# Montana register map
Vendor: ONSemiconductor; Series: Montana Series; File version: 1.0
CPU: CM33 r0p4, little endian, MPU, FPU, 3 interrupt priority bits
Registers are 32-bit, read-write, reset 0x0 unless marked. A register's access mark holds for its fields unless they carry their own. Offsets are from the block's base; [hi:lo] are bit positions; {n}, {i} and the like mark numbered series.

## ACS — Analog Control System
Base 0x40001600
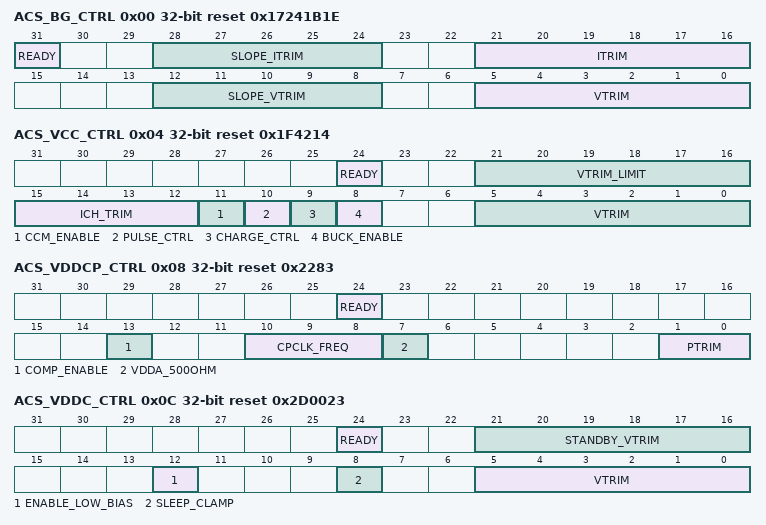
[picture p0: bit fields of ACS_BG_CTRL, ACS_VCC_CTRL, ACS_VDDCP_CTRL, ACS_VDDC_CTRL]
0x00 ACS_BG_CTRL reset 0x17241B1E — Bandgap Control register
  [31] READY ro — Bandgap ready
    0=BG_NOT_READY (Bandgap reference not ready); 1=BG_READY (Bandgap reference ready)
  [28:24] SLOPE_ITRIM — Current temperature coefficient trimming
    23=BG_SLOPE_ITRIM_VALUE (Current temperature dependency 0 ppm/C)
  [21:16] ITRIM — Reference current trimming
    0=BG_ITRIM_0P64UA (0.64 uA); 1=BG_ITRIM_0P65UA (0.65 uA); 35=BG_ITRIM_0P99UA (0.99 uA); 36=BG_ITRIM_1P00UA (1.00 uA); 37=BG_ITRIM_1P01UA (1.01 uA); 62=BG_ITRIM_1P26UA (1.26 uA); 63=BG_ITRIM_1P27UA (1.27 uA)
  [12:8] SLOPE_VTRIM — Voltage temperature coefficient trimming
    27=BG_SLOPE_VTRIM_VALUE (Voltage temperature dependency 0 ppm/C)
  [5:0] VTRIM — Reference voltage trimming (2.5 mV steps)
    0=BG_VTRIM_0P590V (0.610 V); 1=BG_VTRIM_0P595V (0.615 V); 27=BG_VTRIM_0P745V (0.745 V); 28=BG_VTRIM_0P750V (0.750 V); 29=BG_VTRIM_0P755V (0.755 V); 30=BG_VTRIM_0P760V (0.760 V); 31=BG_VTRIM_0P765V (0.765 V); 62=BG_VTRIM_0P900V (0.920 V); 63=BG_VTRIM_0P905V (0.925 V)
0x04 ACS_VCC_CTRL reset 0x1F4214 — DC-DC / LDO Supply Configuration / Control register
  [24] READY ro — Supply ready (only makes sense in test mode)
    0=VCC_NOT_READY (Supply voltage not ready); 1=VCC_READY (Supply voltage ready)
  [21:16] VTRIM_LIMIT — Max VTRIM value that can be used. If VTRIM value is greater it will be limited to this value
    0=VCC_TRIM_LIMIT_1P00V (Output voltage limit 1.00V); 5=VCC_TRIM_LIMIT_1P05V (Output voltage limit 1.05V); 10=VCC_TRIM_LIMIT_1P10V (Output voltage limit 1.10V); 15=VCC_TRIM_LIMIT_1P15V (Output voltage limit 1.15V); 20=VCC_TRIM_LIMIT_1P20V (Output voltage limit 1.20V); 25=VCC_TRIM_LIMIT_1P25V (Output voltage limit 1.25V); 31=VCC_TRIM_LIMIT_1P31V (Output voltage limit 1.31V (This should be the max value allowed)); 35=VCC_TRIM_LIMIT_1P35V (Output voltage limit 1.35V (This is the max value allowed only during RF operation at max output power)); 63=VCC_TRIM_LIMIT_1P63V (Output voltage limit 1.63V)
  [15:12] ICH_TRIM — Inductor charge current trimming
    0=VCC_ICHTRIM_16MA (Charge pump max current to 16 mA); 1=VCC_ICHTRIM_32MA (Charge pump max current to 32 mA); 3=VCC_ICHTRIM_64MA (Charge pump max current to 64 mA); 4=VCC_ICHTRIM_80MA (Charge pump max current to 80 mA); 15=VCC_ICHTRIM_256MA (Charge pump max current to 256 mA)
  [11] CCM_ENABLE — Enable CCM mode
    0=VCC_DCM_MODE (Discontinous current mode); 1=VCC_CCM_MODE (Continuous current mode enabled)
  [10] PULSE_CTRL — Pulse mode control
    0=VCC_SINGLE_PULSE (Single pulse per clock cycle); 1=VCC_MULTI_PULSE (Multi pulses enabled (until VCC > VCC_TRIM))
  [9] CHARGE_CTRL — Charge mode control
    0=VCC_CONSTANT_CHARGE (Constant charge transfer (valid for VBAT > VCC+0.2)); 1=VCC_CONSTANT_IMAX (Constant inductor maximum charge current)
  [8] BUCK_ENABLE — Enable buck converter mode
    0=VCC_LDO (Linear mode); 1=VCC_BUCK (Buck converter mode enabled)
  [5:0] VTRIM — Output voltage trimming configuration in 10 mV steps
    0=VCC_TRIM_1P00V (Output voltage 1.00V); 5=VCC_TRIM_1P05V (Output voltage 1.05V); 10=VCC_TRIM_1P10V (Output voltage 1.10V); 15=VCC_TRIM_1P15V (Output voltage 1.15V); 20=VCC_TRIM_1P20V (Output voltage 1.20V); 25=VCC_TRIM_1P25V (Output voltage 1.25V); 31=VCC_TRIM_1P31V (Output voltage 1.31V (This should be the max value allowed)); 35=VCC_TRIM_1P35V (Output voltage 1.35V (This is the absolute max value allowed, only for RF operation at max output power)); 63=VCC_TRIM_1P63V (Output voltage 1.63V)
0x08 ACS_VDDCP_CTRL reset 0x2283 — Charge Pump control register
  [24] READY ro — Supply ready
    0=VDDCP_NOT_READY (Charge pump voltage not ready); 1=VDDCP_READY (Charge pump voltage ready)
  [13] COMP_ENABLE — Force cp comparator enable
    0=VDDCP_COMP_AUTO (Comparator and resistive divider turned off when not required); 1=VDDCP_COMP_ENABLED (Comparator and resistive divider turned on (retro-compatible))
  [10:8] CPCLK_FREQ — Charge Pump clock frequency during power down modes
    0=VDDCP_CPCLK_32KHZ (CP clock = 32 kHz (WDG_SoC clock)); 1=VDDCP_CPCLK_16KHZ (CP clock = 16 kHz); 2=VDDCP_CPCLK_8KHZ (CP clock = 8 kHz); 3=VDDCP_CPCLK_4KHZ (CP clock = 4 kHz); 4=VDDCP_CPCLK_2KHZ (CP clock = 2 kHz); 5=VDDCP_CPCLK_1KHZ (CP clock = 1 kHz); 6=VDDCP_CPCLK_0P5KHZ (CP clock = 500 Hz); 7=VDDCP_CPCLK_0P25KHZ (CP clock = 250 Hz)
  [7] VDDA_500OHM — VDDA RC low impedance enable
    0=VDDCP_R5000 (5000 Ohm impedance); 1=VDDCP_R500 (500 Ohm impedance)
  [1:0] PTRIM — Output power trimming
    0=VDDCP_PTRIM_4MA (CP max current to 4 mA); 1=VDDCP_PTRIM_8MA (CP max current to 8 mA); 2=VDDCP_PTRIM_12MA (CP max current to 12 mA); 3=VDDCP_PTRIM_16MA (CP max current to 16 mA)
0x0C ACS_VDDC_CTRL reset 0x2D0023 — Digital Core Voltage Regulator control register
  [24] READY ro — Supply ready
    0=VDDC_NOT_READY (Supply voltage not ready); 1=VDDC_READY (Supply voltage ready)
  [21:16] STANDBY_VTRIM — VDDC standby voltage trimming (10 mV steps)
    0=VDDC_STANDBY_TRIM_0P75V (0.75 V); 1=VDDC_STANDBY_TRIM_0P76V (0.76 V); 45=VDDC_STANDBY_TRIM_1P20V (1.2 V); 57=VDDC_STANDBY_TRIM_1P32V (1.32 V); 63=VDDC_STANDBY_TRIM_1P38V (1.38 V)
  [12] ENABLE_LOW_BIAS — Low power mode control
    0=VDDC_NOMINAL_BIAS (Nominal regulator biasing); 1=VDDC_LOW_BIAS (Low regulator biasing)
  [8] SLEEP_CLAMP — Sleep mode clamp control
    0=VDDC_SLEEP_HIZ (Set the output HIZ (floating) in sleep mode); 1=VDDC_SLEEP_GND (Clamp output to ground in sleep mode)
  [5:0] VTRIM — Output voltage trimming configuration in 10 mV steps
    0=VDDC_TRIM_0P75V (0.75 V); 1=VDDC_TRIM_0P76V (0.76 V); 25=VDDC_TRIM_1P00V (1.0 V); 33=VDDC_TRIM_1P08V (1.08 V); 35=VDDC_TRIM_1P10V (1.1 V); 45=VDDC_TRIM_1P20V (1.2 V); 50=VDDC_TRIM_1P25V (1.25 V); 57=VDDC_TRIM_1P32V (1.32 V); 63=VDDC_TRIM_1P38V (1.38 V)
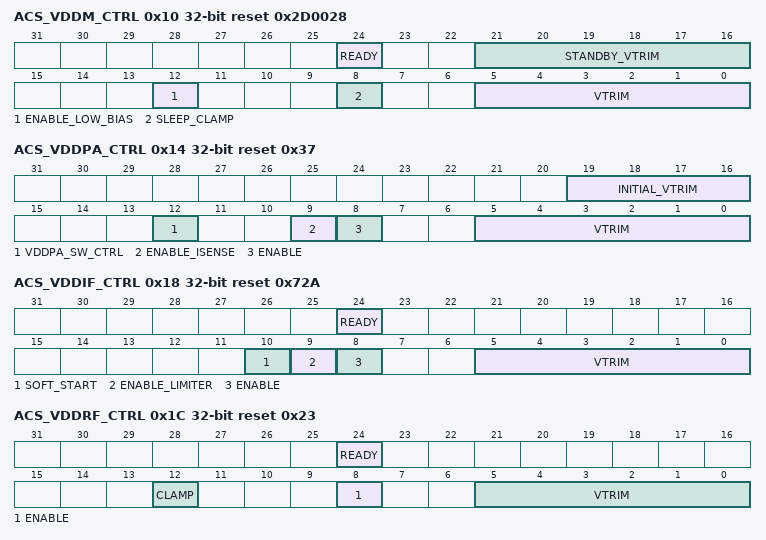
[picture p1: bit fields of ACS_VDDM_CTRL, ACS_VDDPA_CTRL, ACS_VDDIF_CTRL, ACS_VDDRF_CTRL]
0x10 ACS_VDDM_CTRL reset 0x2D0028 — Digital Core Voltage Regulator control register
  [24] READY ro — Supply ready
    0=VDDM_NOT_READY (Supply voltage not ready); 1=VDDM_READY (Supply voltage ready)
  [21:16] STANDBY_VTRIM — VDDM standby voltage trimming (10 mV steps)
    0=VDDM_STANDBY_TRIM_0P75V (0.75 V); 1=VDDM_STANDBY_TRIM_0P76V (0.76 V); 45=VDDM_STANDBY_TRIM_1P20V (1.2 V); 57=VDDM_STANDBY_TRIM_1P32V (1.32 V); 63=VDDM_STANDBY_TRIM_1P38V (1.38 V)
  [12] ENABLE_LOW_BIAS — Low power mode control
    0=VDDM_NOMINAL_BIAS (Nominal regulator biasing); 1=VDDM_LOW_BIAS (Low regulator biasing)
  [8] SLEEP_CLAMP — Sleep mode clamp control
    0=VDDM_SLEEP_HIZ (Set the output HIZ (floating) in sleep mode); 1=VDDM_SLEEP_GND (Clamp output to ground in sleep mode)
  [5:0] VTRIM — Output voltage trimming configuration in 10 mV steps
    0=VDDM_TRIM_0P75V (0.75 V); 1=VDDM_TRIM_0P76V (0.76 V); 25=VDDM_TRIM_1P00V (1.0 V); 33=VDDM_TRIM_1P08V (1.08 V); 35=VDDM_TRIM_1P10V (1.1 V); 40=VDDM_TRIM_1P15V (1.15 V); 45=VDDM_TRIM_1P20V (1.2 V); 50=VDDM_TRIM_1P25V (1.25 V); 57=VDDM_TRIM_1P32V (1.32 V); 63=VDDM_TRIM_1P38V (1.38 V)
0x14 ACS_VDDPA_CTRL reset 0x37 — RF Block Regulator Configuration / Control register
  [19:16] INITIAL_VTRIM — Initial output voltage trimming configuration in 10 mV steps
    0=VDDPA_INITIAL_TRIM_1P05V (1.05 V); 5=VDDPA_INITIAL_TRIM_1P10V (1.10 V); 15=VDDPA_INITIAL_TRIM_1P20V (1.20 V)
  [12] VDDPA_SW_CTRL — Power amplifier supply control
    0=VDDPA_SW_HIZ (Set the output HIZ (floating) in disable mode); 1=VDDPA_SW_VDDRF (Connect switched output to VDDRF regulator (ENABLE bit must be reset))
  [9] ENABLE_ISENSE — Enable current sensing circuit
    0=VDDPA_ISENSE_DISABLE (Disable the VDDPA regulator current sensing circuit); 1=VDDPA_ISENSE_ENABLE (Enable the VDDPA regulator current sensing circuit)
  [8] ENABLE — Enable control
    0=VDDPA_DISABLE (Disable the VDDPA regulator); 1=VDDPA_ENABLE (Enable the VDDPA regulator)
  [5:0] VTRIM — Output voltage trimming configuration in 10 mV steps
    0=VDDPA_TRIM_1P05V (1.05 V); 1=VDDPA_TRIM_1P06V (1.06 V); 54=VDDPA_TRIM_1P59V (1.59 V); 55=VDDPA_TRIM_1P60V (1.60 V); 56=VDDPA_TRIM_1P61V (1.61 V); 63=VDDPA_TRIM_1P68V (1.68 V)
0x18 ACS_VDDIF_CTRL reset 0x72A — VDDIF Block Regulator Configuration / Control register
  [24] READY ro — Supply ready
    0=VDDIF_NOT_READY (Supply voltage not ready); 1=VDDIF_READY (Supply voltage ready)
  [10] SOFT_START — Current limiter threshold setting
    0=VDDIF_LIMITER_70MA (Limiter current threshold at 70mA); 1=VDDIF_LIMITER_4MA (Limiter current threshold at 4mA)
  [9] ENABLE_LIMITER — Enable current limiter circuit
    0=VDDIF_LIMITER_DISABLE (Disable the VDDIF regulator current limiter circuit); 1=VDDIF_LIMITER_ENABLE (Enable the VDDIF regulator current limiter circuit)
  [8] ENABLE — Enable control
    0=VDDIF_DISABLE (Disable the VDDIF regulator); 1=VDDIF_ENABLE (Enable the VDDIF regulator)
  [5:0] VTRIM — Output voltage trimming configuration in 25 mV steps
    0=VDDIF_TRIM_0P750V (0.750V); 1=VDDIF_TRIM_0P775V (0.775V); 41=VDDIF_TRIM_1P775V (1.775V); 42=VDDIF_TRIM_1P800V (1.800V); 43=VDDIF_TRIM_1P825V (1.825V); 62=VDDIF_TRIM_2P300V (2.300V); 63=VDDIF_TRIM_2P325V (2.325V)
0x1C ACS_VDDRF_CTRL reset 0x23 — RF Regulator control register
  [24] READY ro — Supply ready
    0=VDDRF_NOT_READY (Supply voltage not ready); 1=VDDRF_READY (Supply voltage ready)
  [12] CLAMP — Disable mode clamp control
    0=VDDRF_DISABLE_HIZ (Set the output HIZ (floating) in disable mode); 1=VDDRF_DISABLE_GND (Clamp output to ground in disable mode)
  [8] ENABLE — Enable control
    0=VDDRF_DISABLE (Disable the VDDRF regulator); 1=VDDRF_ENABLE (Enable the VDDRF regulator)
  [5:0] VTRIM — Output voltage trimming configuration in 10 mV steps
    0=VDDRF_TRIM_0P75V (0.75 V); 1=VDDRF_TRIM_0P76V (0.76 V); 25=VDDRF_TRIM_1P00V (1.0 V); 33=VDDRF_TRIM_1P08V (1.08 V); 35=VDDRF_TRIM_1P10V (1.1 V); 45=VDDRF_TRIM_1P20V (1.2 V); 57=VDDRF_TRIM_1P32V (1.32 V); 63=VDDRF_TRIM_1P38V (1.38 V)
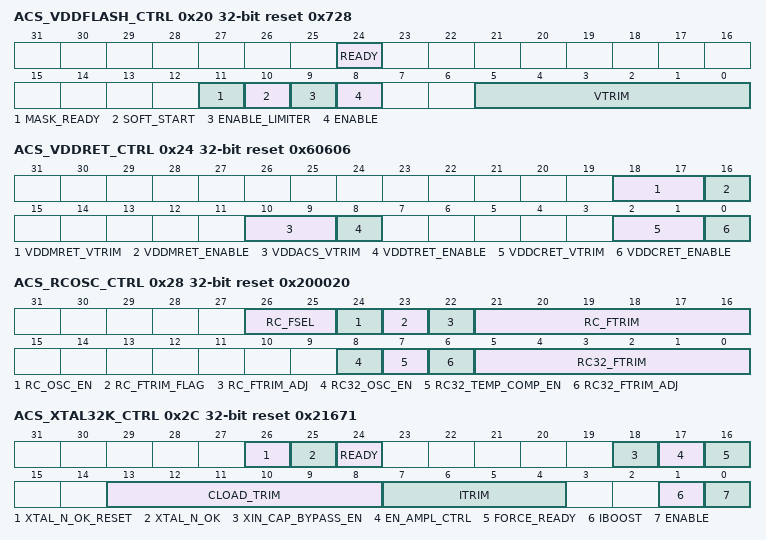
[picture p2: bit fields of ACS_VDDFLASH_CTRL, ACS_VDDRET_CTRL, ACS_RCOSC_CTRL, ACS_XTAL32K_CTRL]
0x20 ACS_VDDFLASH_CTRL reset 0x728 — VDDFLASH Block Regulator Configuration / Control register
  [24] READY ro — Supply ready
    0=VDDFLASH_NOT_READY (Supply voltage not ready); 1=VDDFLASH_READY (Supply voltage ready)
  [11] MASK_READY — Apply a mask to reset logic to ignore VDDFLASH ready signal
    0=VDDFLASH_USE_READY (Reset logic use VDDFLASH ready); 1=VDDFLASH_MASK_READY (Reset ignore VDDFLASH ready)
  [10] SOFT_START — Current limiter threshold setting
    0=VDDFLASH_LIMITER_70MA (Limiter current threshold at 70mA); 1=VDDFLASH_LIMITER_4MA (Limiter current threshold at 4mA)
  [9] ENABLE_LIMITER — Enable current limiter circuit
    0=VDDFLASH_LIMITER_DISABLE (Disable the VDDFLASH regulator current limiter circuit); 1=VDDFLASH_LIMITER_ENABLE (Enable the VDDFLASH regulator current limiter circuit)
  [8] ENABLE — Enable control
    0=VDDFLASH_DISABLE (Disable the VDDFLASH regulator); 1=VDDFLASH_ENABLE (Enable the VDDFLASH regulator)
  [5:0] VTRIM — Output voltage trimming configuration in 25 mV steps
    0=VDDFLASH_TRIM_0P750V (0.750V); 1=VDDFLASH_TRIM_0P775V (0.775V); 39=VDDFLASH_TRIM_1P725V (1.725V); 40=VDDFLASH_TRIM_1P750V (1.750V); 41=VDDFLASH_TRIM_1P775V (1.775V); 62=VDDFLASH_TRIM_2P300V (2.300V); 63=VDDFLASH_TRIM_2P325V (2.325V)
0x24 ACS_VDDRET_CTRL reset 0x60606 — Retention Regulator control register
  [18:17] VDDMRET_VTRIM — VDDMRET retention regulator voltage trimming
    3=VDDMRET_TRIM_VALUE (VDDMRET trimming value)
  [16] VDDMRET_ENABLE — Enable/Disable the VDDMRET retention regulator
    0=VDDMRET_DISABLE (The VDDMRET retention regulator is disabled); 1=VDDMRET_ENABLE (The VDDMRET retention regulator is enabled)
  [10:9] VDDACS_VTRIM — VDDACS regulator voltage trimming
    3=VDDACS_TRIM_VALUE (VDDACS trimming value)
  [8] VDDTRET_ENABLE — Enables the VDDT retention power (activate switch from VDDACS)
    0=VDDTRET_DISABLE (Disable BB timer retention supply (VDDT)); 1=VDDTRET_ENABLE (Enable BB timer retention supply (VDDT))
  [2:1] VDDCRET_VTRIM — VDDCRET Retention regulator voltage trimming
    3=VDDCRET_TRIM_VALUE (VDDCRET trimming value)
  [0] VDDCRET_ENABLE — Enables the VDDCRET Retention regulator
    0=VDDCRET_DISABLE (The VDDCRET retention regulator is disabled); 1=VDDCRET_ENABLE (The VDDCRET retention regulator is enabled)
0x28 ACS_RCOSC_CTRL reset 0x200020 — RC Oscillator control register
  [26:25] RC_FSEL — Select RC oscillator frequency
    0=RC_OSC_3MHZ (The RC Oscillator is at 3 MHz); 1=RC_OSC_12MHZ (The RC Oscillator is at 12 MHz); 2=RC_OSC_24MHZ (The RC Oscillator is at 24 MHz); 3=RC_OSC_48MHZ (The RC Oscillator is at 48 MHz)
  [24] RC_OSC_EN — Enable/Disable the RC Oscillator
    0=RC_OSC_AUTO (The RC Oscillator is in auto mode); 1=RC_OSC_ENABLE (The RC Oscillator is enabled)
  [23] RC_FTRIM_FLAG — RC Oscillator Trimming flag
    0=RC_OSC_UNCALIBRATED (The oscillators are not calibrated); 1=RC_OSC_CALIBRATED (The oscillators are calibrated)
  [22] RC_FTRIM_ADJ — Adjust RC oscillator frequency range
    0=RC_OSC_RANGE_NOM (The RC Oscillator frequency range is nominal); 1=RC_OSC_RANGE_M15 (The RC Osc higher trim freq is decreased by 15 percent)
  [21:16] RC_FTRIM — RC oscillator frequency trimming
    0=RC_OSC_M48 (-48 percent trimming); 1=RC_OSC_M46P5 (-46.5 percent trimming); 32=RC_OSC_NOM (Nominal frequency); 63=RC_OSC_P46P5 (+46.5 percent trimming)
  [8] RC32_OSC_EN — Enable/Disable the 32 kHz RC Oscillator
    0=RC32_OSC_DISABLE (The 32kHz RC Oscillator is disabled); 1=RC32_OSC_ENABLE (The 32kHz RC Oscillator is enabled)
  [7] RC32_TEMP_COMP_EN — Enable/Disable the 32 kHz RC Oscillator
    0=RC32_TEMP_COMP_DISABLE (The 32kHz RC Oscillator temperature compensation is disabled); 1=RC32_TEMP_COMP_ENABLE (The 32kHz RC Oscillator temperature compensation is enabled)
  [6] RC32_FTRIM_ADJ — Adjust 32 kHz RC oscillator frequency range
    0=RC32_OSC_RANGE_NOM (The 32 kHz RC Oscillator frequency range is nominal); 1=RC32_OSC_RANGE_M25 (The 32 kHz RC Oscillator frequency range is lowered by 25 percent)
  [5:0] RC32_FTRIM — 32 kHz RC oscillator frequency trimming
    0=RC32_OSC_M48 (-48 percent trimming); 1=RC32_OSC_M46P5 (-46.5 percent trimming); 32=RC32_OSC_NOM (Nominal frequency); 63=RC32_OSC_P46P5 (+46.5 percent trimming)
0x2C ACS_XTAL32K_CTRL reset 0x21671 (reset mask 0x3073FF3) — Xtal 32 kHz configuration register
  [26] XTAL_N_OK_RESET wo — Reset Xtal not ok sticky flag
    1=XTAL32K_NOT_OK_RESET (Xtal 32K not reset)
  [25] XTAL_N_OK ro — Xtal not ready sticky flag
    0=XTAL_OK (Xtal 32K NOT OK sticky flag was not set); 1=XTAL_N_OK (Xtal 32K NOT OK sticky flag was set)
  [24] READY ro — Xtal ready status
    0=XTAL32K_NOT_OK (Xtal 32K not available); 1=XTAL32K_OK (Xtal 32K is OK)
  [18] XIN_CAP_BYPASS_EN — Switch to bypass the added XIN serial cap to reduce the leakage
    0=XTAL32K_XIN_CAP_BYPASS_DISABLE (Disable the Xtal bypass switch of the XIN serial cap); 1=XTAL32K_XIN_CAP_BYPASS_ENABLE (Enable the Xtal bypass switch of the XIN serial cap)
  [17] EN_AMPL_CTRL — Xtal enable amplitude control (regulation)
    0=XTAL32K_AMPL_CTRL_DISABLE (Xtal 32K amplitude control disabled); 1=XTAL32K_AMPL_CTRL_ENABLE (Xtal 32K amplitude control enabled)
  [16] FORCE_READY — Xtal bypass the ready detector
    0=XTAL32K_NOT_FORCE_READY (Xtal 32K ready not forced); 1=XTAL32K_FORCE_READY (Xtal 32K ready forced)
  [13:8] CLOAD_TRIM — Xtal load capacitance configuration
    0=XTAL32K_CTRIM_0P0PF (0 pF internal capacitor); 1=XTAL32K_CTRIM_0P4PF (0.4 pF internal capacitor); 22=XTAL32K_CTRIM_8P8PF (8.8 pF internal capacitor); 63=XTAL32K_CTRIM_25P2PF (25.2 pF internal capacitor)
  [7:4] ITRIM — Xtal current trimming
    0=XTAL32K_ITRIM_20NA (20 nA startup current); 3=XTAL32K_ITRIM_80NA (80 nA startup current); 7=XTAL32K_ITRIM_160NA (160 nA startup current); 15=XTAL32K_ITRIM_320NA (320 nA startup current)
  [1] IBOOST — Xtal current boosting (4x)
    0=XTAL32K_IBOOST_DISABLE (Disable the Xtal 32 kHz current boosting mode); 1=XTAL32K_IBOOST_ENABLE (Disable the Xtal 32 kHz enable boosting mode (4x itrim currents))
  [0] ENABLE — Enable the Xtal 32 kHz oscillator
    0=XTAL32K_DISABLE (Disable the Xtal 32 kHz oscillator); 1=XTAL32K_ENABLE (Enable the Xtal 32 kHz oscillator)
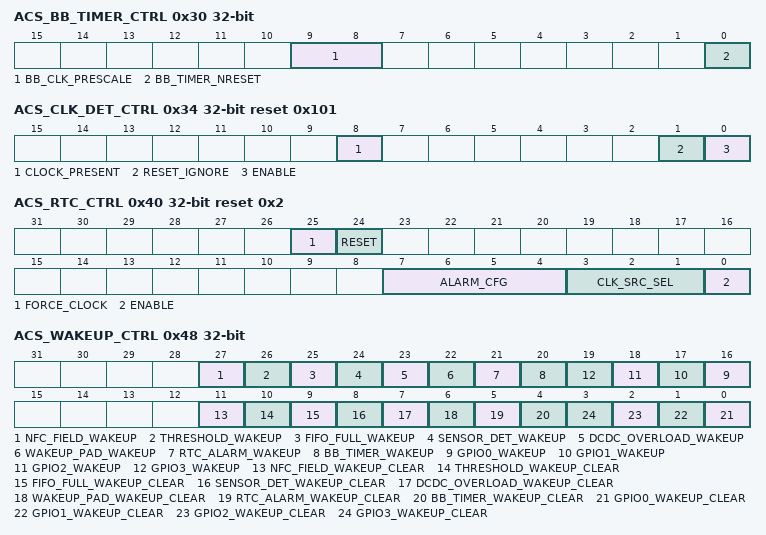
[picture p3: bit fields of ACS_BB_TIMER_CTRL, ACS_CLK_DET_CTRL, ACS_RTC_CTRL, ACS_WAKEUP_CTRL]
0x30 ACS_BB_TIMER_CTRL — Baseband timer and standby clock control register
  [9:8] BB_CLK_PRESCALE — Prescale value for the baseband timer clock
    0=Use 32 kHz clock from RTC; 1=Use 16 kHz clock from RTC (counter bit0); 2=Use 8 kHz clock from RTC (counter bit1); 3=Use 4 kHz clock from RTC (counter bit2)
  [0] BB_TIMER_NRESET — nReset signal for the baseband timer
    0=BB_TIMER_RESET (Baseband timer is in reset state); 1=BB_TIMER_NRESET (Baseband timer reset is released)
0x34 ACS_CLK_DET_CTRL reset 0x101 — Clock Detector configuration register
  [8] CLOCK_PRESENT ro — Clock present flag
    0=ACS_CLK_DET_NO_CLOCK (No clock detected); 1=ACS_CLK_DET_CLOCK_PRESENT (Clock detected)
  [1] RESET_IGNORE — Clock detector reset condition ignore
    1=ACS_CLK_DET_RESET_DISABLE (Clock detector reset condition ignore); 0=ACS_CLK_DET_RESET_ENABLE (Clock detector reset condition accept)
  [0] ENABLE — Clock detector enable
    1=ACS_CLK_DET_ENABLE (Clock detector enable); 0=ACS_CLK_DET_DISABLE (Clock detector disable)
0x38 ACS_RTC_CFG reset 0x7FFF — RTC Timer Counter Preload
  [31:0] START_VALUE — Start value for the RTC timer counter (counts from start_value down to 0)
    0=RTC_CNT_START_0 (Divide by 1); 1=RTC_CNT_START_1 (Divide by 2); 0x7FFF=RTC_CNT_START_32767 (Divide by 32768); 0xFFFFFFFF=RTC_CNT_START_4294967295 (Divide by 2**32)
0x3C ACS_RTC_COUNT ro — RTC Timer Counter Current Value
  [31:0] VALUE — RTC timer current value
0x40 ACS_RTC_CTRL reset 0x2 (reset mask 0xFF) — RTC control Register
  [25] FORCE_CLOCK wo — Force a clock on RTC timer (Test Purpose)
    1=RTC_FORCE_CLOCK (Clock the RTC timer (has an effect only if the source clock is low))
  [24] RESET wo — Reset the RTC timer
    1=RTC_RESET (The RTC timer is reset)
  [7:4] ALARM_CFG — Configure RTC timer alarm
    0=RTC_ALARM_DISABLE (RTC alarm is disabled); 1=RTC_ALARM_7P8125MS (RTC alarm on counter bit 7th rising edge (7.8125 ms = 2^(n+1)*1/32.768kHz)); 2=RTC_ALARM_15P625MS (RTC alarm on counter bit 8th rising edge (15.625 ms = 2^(n+1)*1/32.768kHz)); 3=RTC_ALARM_31P25MS (RTC alarm on counter bit 9th rising edge (31.25 ms = 2^(n+1)*1/32.768kHz)); 4=RTC_ALARM_62P5MS (RTC alarm on counter bit 10th rising edge (62.5 ms = 2^(n+1)*1/32.768kHz)); 5=RTC_ALARM_125MS (RTC alarm on counter bit 11th rising edge (125 ms = 2^(n+1)*1/32.768kHz)); 6=RTC_ALARM_250MS (RTC alarm on counter bit 12th rising edge (250 ms = 2^(n+1)*1/32.768kHz)); 7=RTC_ALARM_500MS (RTC alarm on counter bit 13th rising edge (500 ms = 2^(n+1)*1/32.768kHz)); 8=RTC_ALARM_1S (RTC alarm on counter bit 14th rising edge (1 s = 2^(n+1)*1/32.768kHz)); 9=RTC_ALARM_2S (RTC alarm on counter bit 15th rising edge (2 s = 2^(n+1)*1/32.768kHz)); 10=RTC_ALARM_4S (RTC alarm on counter bit 16th rising edge (4 s = 2^(n+1)*1/32.768kHz)); 11=RTC_ALARM_8S (RTC alarm on counter bit 17th rising edge (8 s = 2^(n+1)*1/32.768kHz)); 12=RTC_ALARM_16S (RTC alarm on counter bit 18th rising edge (16 s = 2^(n+1)*1/32.768kHz)); 13=RTC_ALARM_32S (RTC alarm on counter bit 19th rising edge (32 s = 2^(n+1)*1/32.768kHz)); 14=RTC_ALARM_64S (RTC alarm on counter bit 20th rising edge (64 s = 2^(n+1)*1/32.768kHz)); 15=RTC_ALARM_ZERO (RTC alarm on (down with RTC clock input is 32.768 kHz) counter reaching zero (up to 36.4 hours))
  [3:1] CLK_SRC_SEL — Select the RTC, standby, bb timer, and sensor block clock source
    0=RTC_CLK_SRC_RC_OSC (Select the internal RC Oscillator clock); 1=RTC_CLK_SRC_XTAL32K (Select the internal XTAL 32 kHz clock); 2=RTC_CLK_SRC_GPIO0 (Select GPIO0 as a clock source); 3=RTC_CLK_SRC_GPIO1 (Select GPIO1 as a clock source); 4=RTC_CLK_SRC_GPIO2 (Select GPIO2 as a clock source (not functional, test purpose only)); 5=RTC_CLK_SRC_GPIO3 (Select GPIO3 as a clock source (not functional, test purpose only))
  [0] ENABLE — Enable counter and RTC interrupt every 1s
    0=RTC_DISABLE (The RTC is disabled); 1=RTC_ENABLE (The RTC is enabled)
0x44 ACS_PWR_MODES_CTRL reset not defined — Power Modes control Register
  [31:0] POWER_MODE wo — 32-bit key to enter STANDBY, SLEEP, or DEEP_SLEEP mode. This register must be written using a 32-bit access.
    0=PWR_RUN_MODE (Keep the system in normal RUN mode); 0x9B1D79A0=PWR_STANDBY_MODE (Enter STANDBY mode); 0xE0045650=PWR_SLEEP_MODE (Enter SLEEP mode); 0x53C02890=PWR_DEEP_SLEEP_MODE (Enter DEEP_SLEEP mode)
0x48 ACS_WAKEUP_CTRL (reset mask 0xFFF0000) — Wake-Up control / Status Register
  [27] NFC_FIELD_WAKEUP ro
    0=WAKEUP_NFC_FIELD_EVENT_NOT_SET (NFC field has not triggered a wakeup event); 1=WAKEUP_NFC_FIELD_EVENT_SET (NFC field has triggered a wakeup event at least once)
  [26] THRESHOLD_WAKEUP ro
    0=WAKEUP_THRESHOLD_EVENT_NOT_SET (The ADC threshold has not triggered a wakeup event); 1=WAKEUP_THRESHOLD_EVENT_SET (The ADC threshold has triggered a wakeup event at least once)
  [25] FIFO_FULL_WAKEUP ro
    0=WAKEUP_FIFO_FULL_EVENT_NOT_SET (The ADC FIFO has not triggered a wakeup event); 1=WAKEUP_FIFO_FULL_EVENT_SET (The ADC FIFO has triggered a wakeup event at least once)
  [24] SENSOR_DET_WAKEUP ro
    0=WAKEUP_SENSOR_DET_EVENT_NOT_SET (Sensor detector has not triggered a wakeup event); 1=WAKEUP_SENSOR_DET_EVENT_SET (Sensor detector has triggered a wakeup event at least once)
  [23] DCDC_OVERLOAD_WAKEUP ro
    0=WAKEUP_DCDC_OVERLOAD_EVENT_NOT_SET (DCDC overload has not triggered a wakeup event); 1=WAKEUP_DCDC_OVERLOAD_EVENT_SET (DCDC overload has triggered a wakeup event at least once)
  [22] WAKEUP_PAD_WAKEUP ro
    0=WAKEUP_PAD_EVENT_NOT_SET (Wakeup pad has not triggered a wakeup event); 1=WAKEUP_PAD_EVENT_SET (Wakeup pad has triggered a wakeup event at least once)
  [21] RTC_ALARM_WAKEUP ro
    0=WAKEUP_RTC_ALARM_EVENT_NOT_SET (RTC alarm has not triggered a wakeup event); 1=WAKEUP_RTC_ALARM_EVENT_SET (RTC alarm has triggered a wakeup event at least once)
  [20] BB_TIMER_WAKEUP ro
    0=WAKEUP_BB_TIMER_EVENT_NOT_SET (BB timer has not triggered a wakeup event); 1=WAKEUP_BB_TIMER_EVENT_SET (BB timer has triggered a wakeup event at least once)
  [n+16] GPIO{n}_WAKEUP ro (n=0..3)
    0=WAKEUP_GPIO{n}_EVENT_NOT_SET (GPIO{n} has not triggered a wakeup event); 1=WAKEUP_GPIO{n}_EVENT_SET (GPIO{n} has triggered a wakeup event at least once)
  [11] NFC_FIELD_WAKEUP_CLEAR wo
    1=WAKEUP_NFC_FIELD_EVENT_CLEAR (Reset the sticky WAKEUP_NFC_FIELD_EVENT flag)
  [10] THRESHOLD_WAKEUP_CLEAR wo
    1=THRESHOLD_FULL_EVENT_CLEAR (Reset the sticky WAKEUP_THRESHOLD_EVENT flag)
  [9] FIFO_FULL_WAKEUP_CLEAR wo
    1=WAKEUP_FIFO_FULL_EVENT_CLEAR (Reset the sticky WAKEUP_FIFO_FULL_EVENT flag)
  [8] SENSOR_DET_WAKEUP_CLEAR wo
    1=WAKEUP_SENSOR_DET_EVENT_CLEAR (Reset the sticky WAKEUP_SENSOR_DET_EVENT flag)
  [7] DCDC_OVERLOAD_WAKEUP_CLEAR wo
    1=WAKEUP_DCDC_OVERLOAD_EVENT_CLEAR (Reset the sticky WAKEUP_DCDC_OVERLOAD flag)
  [6] WAKEUP_PAD_WAKEUP_CLEAR wo
    1=WAKEUP_PAD_EVENT_CLEAR (Reset the sticky WAKEUP_PAD_EVENT flag)
  [5] RTC_ALARM_WAKEUP_CLEAR wo
    1=WAKEUP_RTC_ALARM_EVENT_CLEAR (Reset the sticky WAKEUP_RTC_ALARM_EVENT flag)
  [4] BB_TIMER_WAKEUP_CLEAR wo
    1=WAKEUP_BB_TIMER_CLEAR (Reset the sticky WAKEUP_BB_TIMER_EVENT flag)
  [n] GPIO{n}_WAKEUP_CLEAR wo (n=0..3)
    1=WAKEUP_GPIO{n}_EVENT_CLEAR (Reset the sticky WAKEUP_GPIO{n}_EVENT flag)
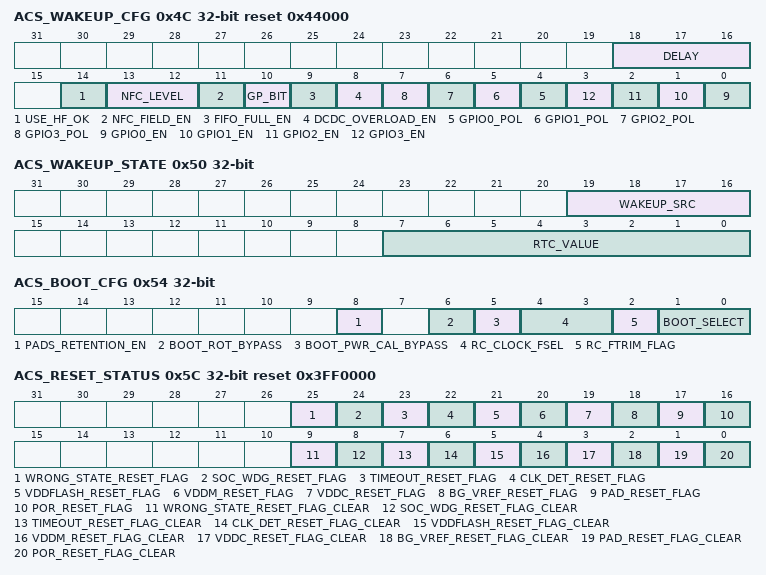
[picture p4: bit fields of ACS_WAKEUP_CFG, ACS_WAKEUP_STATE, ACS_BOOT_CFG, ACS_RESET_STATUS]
0x4C ACS_WAKEUP_CFG reset 0x44000 — Wakeup configuration
  [18:16] DELAY — Delay from VDDC ready & VDDM ready to digital clock enable (power of 2)
    0=WAKEUP_DELAY_1 (Wait for 1 32kHz clock cycle); 1=WAKEUP_DELAY_2 (Wait for 2 32kHz clock cycles); 2=WAKEUP_DELAY_4 (Wait for 4 32kHz clock cycles); 3=WAKEUP_DELAY_8 (Wait for 8 32kHz clock cycles); 4=WAKEUP_DELAY_16 (Wait for 16 32kHz clock cycles); 5=WAKEUP_DELAY_32 (Wait for 32 32kHz clock cycles); 6=WAKEUP_DELAY_64 (Wait for 64 32kHz clock cycles); 7=WAKEUP_DELAY_128 (Wait for 128 32kHz clock cycles)
  [14] USE_HF_OK — Ignore the status of HF clock frequency to wake-up the SoC
    0=WAKEUP_NOT_USE_HF_OK (Wake-up don't use HF OK); 1=WAKEUP_USE_HF_OK
  [13:12] NFC_LEVEL — Level of the NFC field to wake up the SoC
    0=NFC_FIELD_0 (Level 0 of the field triggers wake-up); 1=NFC_FIELD_1 (Level 1 of the field triggers wake-up); 2=NFC_FIELD_2 (Level 2 of the field triggers wake-up)
  [11] NFC_FIELD_EN — Enable the wake-up on NFC field
    0=WAKEUP_NFC_FIELD_DISABLE (Disable NFC field wake-up); 1=WAKEUP_NFC_FIELD_ENABLE (Enable NFC field interrupt wake-up)
  [10] GP_BIT — This bit is a RW flop that is not used by the HW
  [9] FIFO_FULL_EN — Enable the wake-up on full FIFO
    0=WAKEUP_FIFO_DISABLE (Disable the wake-up functionality on the ADC FIFO); 1=WAKEUP_FIFO_ENABLE (Enable the wake-up functionality on the ADC FIFO)
  [8] DCDC_OVERLOAD_EN — Enable / Disable the Wake-up functionality on the DCDC overload flag
    0=WAKEUP_DCDC_OVERLOAD_DISABLE (Disable the Wake-up functionality on the DCDC overload flag); 1=WAKEUP_DCDC_OVERLOAD_ENABLE (Enable the Wake-up functionality on the DCDC overload flag)
  [n+4] GPIO{n}_POL (n=0..3) — Wake-up polarity on the GPIO{n} pad
    0=WAKEUP_GPIO{n}_RISING (Wake-up on the GPIO{n} rising edge); 1=WAKEUP_GPIO{n}_FALLING (Wake-up on the GPIO{n} falling edge)
  [n] GPIO{n}_EN (n=0..3) — Enable the wake-up functionality on the GPIO{n} pad
    0=WAKEUP_GPIO{n}_DISABLE (Disable the wake-up functionality on the GPIO{n} pad); 1=WAKEUP_GPIO{n}_ENABLE (Enable the wake-up functionality on the GPIO{n} pad)
0x50 ACS_WAKEUP_STATE ro — RTC Timer wakeup value and wakeup source
  [19:16] WAKEUP_SRC — Status register indicates the last wake-up source
    11=WAKEUP_DUE_TO_NFC_FIELD (The last wake-up was due to the NFC field); 10=WAKEUP_DUE_TO_THRESHOLD (The last wake-up was due to the ADC threshold); 9=WAKEUP_DUE_TO_FIFO (The last wake-up was due to the ADC FIFO); 8=WAKEUP_DUE_TO_SENSOR_DET (The last wake-up was due to the sensor detector); 7=WAKEUP_DUE_TO_DCDC_OVERLOAD (The last wake-up was due to the dcdc overload); 6=WAKEUP_DUE_TO_WAKEUP_PAD (The last wake-up was due to the WAKEUP pad); 5=WAKEUP_DUE_TO_RTC_ALARM (The last wake-up was due to the RTC Timer alarm); 4=WAKEUP_DUE_TO_BB_TIMER (The last wake-up was due to the baseband timer alarm); {v}=WAKEUP_DUE_TO_GPIO{v} (The last wake-up was due to the GPIO{v} pad) (v=0..3)
  [7:0] RTC_VALUE — RTC counter value captured at wakeup event (only 8 LSBs, corresponds to 7.8 ms)
0x54 ACS_BOOT_CFG — Boot configuration
  [8] PADS_RETENTION_EN — Enable / Disable the retention mode of the pads
    0=PADS_RETENTION_DISABLE (Disable the pad retention mode); 1=PADS_RETENTION_ENABLE (Enable the pad retention mode)
  [6] BOOT_ROT_BYPASS — Boot bypass execution of root of trust
    0=BOOT_ROT_BYPASS_DISABLE (ROM will execute ROT); 1=BOOT_ROT_BYPASS_ENABLE (ROM will not execute ROT)
  [5] BOOT_PWR_CAL_BYPASS — Boot bypass execution of system calibration
    0=BOOT_PWR_CAL_BYPASS_DISABLE (ROM will execute calibration of system); 1=BOOT_PWR_CAL_BYPASS_ENABLE (ROM will not execute calibration of system)
  [4:3] RC_CLOCK_FSEL ro — RC oscillator clock multiplier read only flag (mirror of CLOCK_MULT of ACS_RCOSC_CTRL register)
    0=RC_OSC_STATUS_3MHZ (The RC Oscillator is at 3 MHz); 1=RC_OSC_STATUS_12MHZ (The RC Oscillator is at 12 MHz); 2=RC_OSC_STATUS_24MHZ (The RC Oscillator is at 24 MHz); 3=RC_OSC_STATUS_48MHZ (The RC Oscillator is at 48 MHz)
  [2] RC_FTRIM_FLAG ro — RC oscillator trimming read only flag (mirror of FTRIM_FLAG of ACS_RCOSC_CTRL register
    0=RC_OSC_STATUS_UNCALIBRATED (The oscillators are not calibrated); 1=RC_OSC_STATUS_CALIBRATED (The oscillators are calibrated)
  [1:0] BOOT_SELECT — Boot selection to indicate boot source
    0=BOOT_FLASH_XTAL_DISABLE (The CM33 executes code from the flash and the XTAL will not be started at boot); 1=BOOT_CUSTOM (The CM33 executes code from the address specified in the wakeup information in retention RAM and the XTAL will not be started at boot); 2=BOOT_FLASH_XTAL_DEFAULT_TRIM (The CM33 executes code from the flash and the XTAL will be started at boot with the default trim); 3=BOOT_FLASH_XTAL_CUSTOM_TRIM (The CM33 executes code from the flash and the XTAL will be started at boot with trim from ACS_WAKEUP_GP_DATA)
0x58 ACS_BOOT_GP_DATA — Boot control Register registers
  [31:0] GP_DATA — 32-bit General-Purpose RW Data
0x5C ACS_RESET_STATUS reset 0x3FF0000 (reset mask 0x3FF0000) — ACS reset source status registers
  [25] WRONG_STATE_RESET_FLAG ro — Sticky flag that detects that a wrong state reset occurred
    0=WRONG_STATE_RESET_FLAG_NOT_SET (The wrong state reset has not triggered at least once); 1=WRONG_STATE_RESET_FLAG_SET (The wrong state reset was triggered at least once since this status bit was last cleared)
  [24] SOC_WDG_RESET_FLAG ro — Sticky flag that detects that a SoC watchdog reset occurred
    0=SOC_WDG_RESET_FLAG_NOT_SET (The SoC watchdog reset has not triggered at least once); 1=SOC_WDG_RESET_FLAG_SET (The SoC watchdog reset was triggered at least once since this status bit was last cleared)
  [23] TIMEOUT_RESET_FLAG ro — Sticky flag that detects that a timeout in the power up sequence
    0=TIMEOUT_RESET_FLAG_NOT_SET (The timeout reset has not triggered at least once); 1=TIMEOUT_RESET_FLAG_SET (The timeout reset was triggered at least once since this status bit was last cleared)
  [22] CLK_DET_RESET_FLAG ro — Sticky flag that detects that a clock detector reset occurred
    0=CLK_DET_RESET_FLAG_NOT_SET (The clock detector reset has not triggered at least once); 1=CLK_DET_RESET_FLAG_SET (The clock detector reset was triggered at least once since this status bit was last cleared)
  [21] VDDFLASH_RESET_FLAG ro — Sticky flag that detects that a VDDFLASH reset occurred (triggered by VDDFLASH_ready = 0)
    0=VDDFLASH_RESET_FLAG_NOT_SET (The VDDFLASH reset has not triggered at least once); 1=VDDFLASH_RESET_FLAG_SET (The VDDFLASH reset was triggered at least once since this status bit was last cleared)
  [20] VDDM_RESET_FLAG ro — Sticky flag that detects that a VDDM reset occurred (triggered by VDDM_ready = 0)
    0=VDDM_RESET_FLAG_NOT_SET (The VDDM reset has not triggered at least once); 1=VDDM_RESET_FLAG_SET (The VDDM reset was triggered at least once since this status bit was last cleared)
  [19] VDDC_RESET_FLAG ro — Sticky flag that detects that a VDDC reset occurred (triggered by VDDC_ready = 0)
    0=VDDC_RESET_FLAG_NOT_SET (The VDDC reset has not triggered at least once); 1=VDDC_RESET_FLAG_SET (The VDDC reset was triggered at least once since this status bit was last cleared)
  [18] BG_VREF_RESET_FLAG ro — Sticky flag that detects that a Bandagap reference voltage reset occurred
    0=BG_VREF_RESET_FLAG_NOT_SET (The Bandagap reference voltage reset has not triggered at least once); 1=BG_VREF_RESET_FLAG_SET (The Bandagap reference voltage was triggered at least once since this status bit was last cleared)
  [17] PAD_RESET_FLAG ro — Sticky flag that detects that a reset occurred due to pad NRESET
    0=PAD_RESET_FLAG_NOT_SET (The NRESET pad reset has not triggered at least once); 1=PAD_RESET_FLAG_SET (The NRESET pad reset was triggered at least once since this status bit was last cleared)
  [16] POR_RESET_FLAG ro — Sticky flag that detects that a POR reset occurred
    0=POR_RESET_FLAG_NOT_SET (The POR reset has not triggered at least once); 1=POR_RESET_FLAG_SET (The POR reset was triggered at least once since this status bit was last cleared)
  [9] WRONG_STATE_RESET_FLAG_CLEAR wo — Reset the sticky WRONG_STATE_RESET flag.
    1=WRONG_STATE_RESET_FLAG_CLEAR (Reset the sticky WRONG_STATE_RESET flag.)
  [8] SOC_WDG_RESET_FLAG_CLEAR wo — Reset the sticky SOC_WDG_RESET flag.
    1=SOC_WDG_RESET_FLAG_CLEAR (Reset the sticky SOC_WDG_RESET flag.)
  [7] TIMEOUT_RESET_FLAG_CLEAR wo — Reset the sticky TIMEOUT_RESET flag.
    1=TIMEOUT_RESET_FLAG_CLEAR (Reset the sticky TIMEOUT_RESET flag.)
  [6] CLK_DET_RESET_FLAG_CLEAR wo — Reset the sticky CLK_DET_RESET flag.
    1=CLK_DET_RESET_FLAG_CLEAR (Reset the sticky CLK_DET_RESET flag.)
  [5] VDDFLASH_RESET_FLAG_CLEAR wo — Reset the sticky VDDFLASH_RESET flag.
    1=VDDFLASH_RESET_FLAG_CLEAR (Reset the sticky VDDFLASH_RESET flag.)
  [4] VDDM_RESET_FLAG_CLEAR wo — Reset the sticky VDDM_RESET flag.
    1=VDDM_RESET_FLAG_CLEAR (Reset the sticky VDDM_RESET flag.)
  [3] VDDC_RESET_FLAG_CLEAR wo — Reset the sticky VDDC_RESET flag.
    1=VDDC_RESET_FLAG_CLEAR (Reset the sticky VDDC_RESET flag.)
  [2] BG_VREF_RESET_FLAG_CLEAR wo — Reset the sticky BG_VREF_RESET flag.
    1=BG_VREF_RESET_FLAG_CLEAR (Reset the sticky BG_VREF_RESET flag.)
  [1] PAD_RESET_FLAG_CLEAR wo — Reset the sticky PAD_RESET flag.
    1=PAD_RESET_FLAG_CLEAR (Reset the sticky PAD_RESET flag.)
  [0] POR_RESET_FLAG_CLEAR wo — Reset the sticky POR_RESET flag.
    1=POR_RESET_FLAG_CLEAR (Reset the sticky POR_RESET flag.)
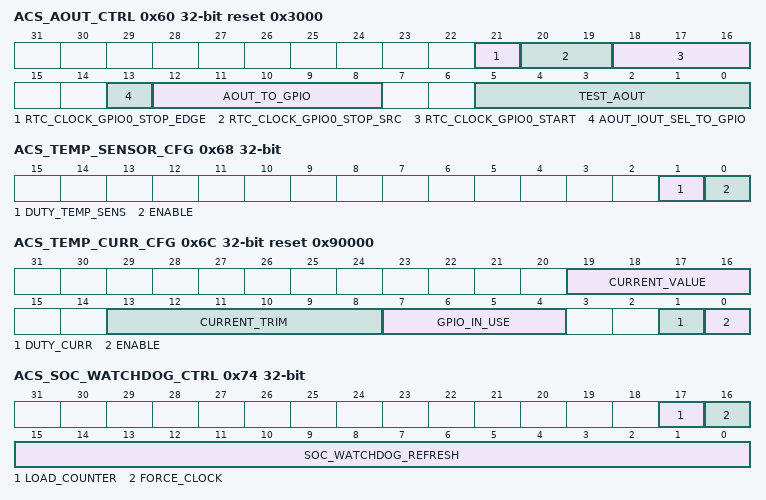
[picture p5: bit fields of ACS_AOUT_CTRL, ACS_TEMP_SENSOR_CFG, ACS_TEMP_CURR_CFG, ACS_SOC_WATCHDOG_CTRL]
0x60 ACS_AOUT_CTRL reset 0x3000 — Analog output configuration register
  [21] RTC_CLOCK_GPIO0_STOP_EDGE — Stop edge for RTC clock output on AOUT
    0=GPIO0_RTC_CLK_STOP_RISING (Stop to output RTC clock on rising edge); 1=GPIO0_RTC_CLK_STOP_FALLING (Stop to output RTC clock on falling edge)
  [20:19] RTC_CLOCK_GPIO0_STOP_SRC — Stop source for RTC clock output on AOUT
    {v}=GPIO0_RTC_CLK_STOP_GPIO{v} (Stop to output RTC clock on GPIO{v} event) (v=0..3)
  [18:16] RTC_CLOCK_GPIO0_START — Start event for RTC clock output on AOUT (RTC prescaler and counter need to be enabled)
    0=GPIO0_RTC_CLK_DISABLE (No start event (GPIO0 not driven)); 1=GPIO0_RTC_CLK_125MS (Start to output RTC clock every 125 ms); 2=GPIO0_RTC_CLK_250MS (Start to output RTC clock every 250 ms); 3=GPIO0_RTC_CLK_500MS (Start to output RTC clock every 500 ms); 4=GPIO0_RTC_CLK_1S (Start to output RTC clock every 1 s); 5=GPIO0_RTC_CLK_2S (Start to output RTC clock every 2 s); 6=GPIO0_RTC_CLK_4S (Start to output RTC clock every 4 s); 7=GPIO0_RTC_CLK_8S (Start to output RTC clock every 8 s)
  [13] AOUT_IOUT_SEL_TO_GPIO — Selection between AOUT voltage / current or thermistor current source to GPIO
    0=SEL_IOUT_TO_GPIO (Select thermistor IOUT current source); 1=SEL_AOUT_TO_GPIO (Select AOUT voltage / current source)
  [12:8] AOUT_TO_GPIO — Select to which GPIO the AOUT voltage or PTAT current provided
    {v}=Select GPIO[{v}] as output (v=0..15); 16=AOUT_NOT_CONNECTED_TO_GPIO (None selected)
  [5:0] TEST_AOUT — AOUT test signal selection
    0=AOUT_VSSA (AOUT grounded); 1=AOUT_VCC (VCC); 2=AOUT_IPTAT (Bandgap ptat pmos current source (typically 11nA at 25C)); 3=AOUT_IVBE (Bandgap vbe ptat current source (typically 18nA at 25C)); 4=AOUT_IREF_1U (Bandgap 1uA pmos current source); 5=AOUT_IREF_50N (Bandgap 50nA pmos current source); 6=AOUT_IREF_10N (Bandgap 10nA nmos current source); 7=AOUT_VREG_BG (Bandgap regulated supply voltage / flash reference voltage (1.2V)); 8=AOUT_VREF_0P75V (Bandgap reference voltage 0p75V (test purpose only, can reset the chip)); 9=AOUT_VREF_0P75V_buf (Bandgap reference voltage 0p75V after internal buffer); 10=AOUT_VREF_0P67V (Bandgap reference voltage 0p67V (test purpose only, can reset the chip)); 11=AOUT_WE_DAC (Bandgap we_dac reference voltage. Depending on WEDAC_LOW and WEDAC_HIGH configuration in sensor we_dac will toggle between the two values (ACS will change the bandgap trimming accordingly) (test purpose only, can reset the chip)); 12=AOUT_TEMP_SENSOR_VPTAT (Temperature sensor output voltage (typically 0.95V at 25C)); 13=AOUT_ADC_SENSOR_IRANGE (ADC sensor irange); 14=AOUT_LSAD_INTERNAL_VREF (LSAD internal vref (1.0V)); 15=AOUT_THERMISTOR_CURRENT (Thermistor current); 16=AOUT_IREF_1N_OUTPUT (PMU PTAT iref current source (typically 0.9uA at 25C)); 17=AOUT_VDDACS_OUTPUT (PMU vddacs voltage); 18=AOUT_RC_INTENAL_SUPPLY (RC intenal supply (typically 0.8V at 25C)); 19=AOUT_RC32_INTENAL_SUPPLY (RC32 intenal supply (typically 0.65V at 25C)); 20=AOUT_VDDA_SW (Vdda switch voltage); 21=AOUT_VDDSYN_SW (Vddsyn switch voltage); 22=AOUT_VDDRF_SW (Vddrf switch voltage); 23=AOUT_VDDT (VDDT switch voltage); 24=AOUT_VDDCCAO (VDDCCAO switch voltage); 25=AOUT_VDDSENSOR (VDDSENSOR switch voltage); 26=AOUT_VDDM (VDDM voltage output); 27=AOUT_VDDC (VDDC voltage output); 28=AOUT_VDDPA (VDDPA voltage output); 29=AOUT_VDDPA_ISENSE (VDDPA current sensing (image of VDDPA load for test purpose, 0V when VDDPA is unloaded)); 30=AOUT_FLASH1_TM0 (Instance Flash 1 TM0 connected to AOUT); 31=AOUT_FLASH0_TM0 (Instance Flash 0 TM0 connected to AOUT); 32=AOUT_VDDCP (VDDCP voltage output); 33=AOUT_VDDRF (VDDRF voltage output); 34=AOUT_VDDIF (VDDIF voltage output); 35=AOUT_VDDFLASH (VDDFLASH voltage output); 36=AOUT_HIZ (HIZ (mesure leakage)); 37=AOUT_RC32_IBP_12N_NTC (RC32 NTC current); 38=AOUT_SP1 (Analog spare signal 1, (not implemented yet but ADC sensor offset if a SV4 is done)); 39=AOUT_SP2 (Analog spare signal 2); 40=AOUT_SP3 (Analog spare signal 3); 41=DOUT_ADC_PULSE (adc_pulse signal from sensor IF (through ACS)); 42=DOUT_SENSOR_DET (sensor_det_active signal from detector); 43=DOUT_BG_READY (Bandgap ready signal); 44=DOUT_VDDRF_READY (vddrf ready signal); 45=DOUT_VDDC_READY (Vddc ready signal); 46=DOUT_VDDM_READY (Vddm ready signal); 47=DOUT_VDDCP_READY (vddcp ready signal); 48=DOUT_VDDIF_READY (vddif ready signal); 49=DOUT_VDDFLASH_READY (vddflash ready signal); 50=DOUT_CLK_PRESENT (Clock present from clock detector); 51=DOUT_XTAL_OK (Xtal 32kHz ok); 52=DOUT_XTAL_CLK (Xtal 32kHz clock); 53=DOUT_RC32_CLK (RC 32kHz clock); 54=DOUT_DCDC_ACTIVATED (DC-DC converter activated signal); 55=DOUT_DCDC_OVERLOAD (DC-DC converter overload signal); 56=DOUT_DCDC_VCC_READY (DC-DC converter vcc ready signal); 57=DOUT_NFC_WAKEUP (NFC wakeup signal); {v}=DOUT_NFC_FIELD_{v-58} (Nfc_Field {v-58}) (v=58..61); 62=DOUT_SP1 (Digital spare signal 1); 63=DOUT_SP2 (Digital spare signal 2)
0x64 ACS_JIC_READ ro reset 0xFF — Just In Case register in the ACS block
  [7:0] BYTE0_RO — JIC read only register bits (returning signals from analog part: tied to 1)
0x68 ACS_TEMP_SENSOR_CFG — Temperature sensor configuration register
  [1] DUTY_TEMP_SENS — Duty cycling temperature sensor
    0=LSAD_TEMP_SENS_NORMAL (Normal mode: temperature sensor enable only controlled by TEMP_SENS_ENABLE); 1=LSAD_TEMP_SENS_DUTY (Duty cycling temperature sensor (enabled only during LSAD conversion))
  [0] ENABLE — Internal temperature sensor enable
    0=TEMP_SENS_DISABLE (Disable the internal Temperature Sensor); 1=TEMP_SENS_ENABLE (Enable the internal Temperature Sensor)
0x6C ACS_TEMP_CURR_CFG reset 0x90000 — Temperature current configuratio
  [19:16] CURRENT_VALUE — Temperature current value
    0=TEMP_CURR_1UA (Temperature current set to 1 uA); 9=TEMP_CURR_10UA (Temperature current set to 10 uA); 15=TEMP_CURR_16UA (Temperature current set to 16 uA)
  [13:8] CURRENT_TRIM — Temperature current trimming
    0=TEMP_CURR_TRIM_M32 (-10 percent trimming); 32=TEMP_CURR_TRIM_0 (Default trimming); 63=TEMP_CURR_TRIM_P31 (+10 percent trimming)
  [7:4] GPIO_IN_USE — GPIO from which the duty cycle is used
    {v}=TEMP_CURR_GPIO{v} (Duty cycle of GPIO{v} is used) (v=0..15)
  [1] DUTY_CURR — Duty cycling current enable
    0=LSAD_CURR_NORMAL (Normal mode: current enable only controlled by CURR_ENABLE); 1=LSAD_CURR_DUTY (Duty cycling current enable (enabled only during LSAD conversion))
  [0] ENABLE — Temperature current enable
    0=TEMP_CURR_DISABLE (Disable the temperature current); 1=TEMP_CURR_ENABLE (Enable the temperature current)
0x70 ACS_SOC_WATCHDOG_CFG — SoC Watchdog Configuration Register
  [0] BYPASS_IN_SLEEP — Allows to enter in a sleep mode that bypass the watchog. This configuration bit is only used when the system goes to sleep power down. Once is sleep in sleep and during the others mode this bit is not used
    0=SOC_WATCHDOG_IN_SLEEP (Use SoC watchdog in sleep); 1=SOC_WATCHDOG_BYPASS_IN_SLEEP (Bypass SoC wathdog in sleep)
0x74 ACS_SOC_WATCHDOG_CTRL reset not defined — SoC Watchdog Refresh Control Register
  [17] LOAD_COUNTER wo — The SoC watchdog will be loaded with value MAX-1 if EN_TEST pad is one and the FORCE_CLOCK is also set at the same time
    1=SOC_WATCHDOG_LOAD (Load the SoC watchdog timer)
  [16] FORCE_CLOCK wo — Force a clock on SoC watchdog timer (Test Purpose, only when EN_TEST=1)
    1=SOC_WATCHDOG_FORCE_CLOCK (Clock the SoC watchdog timer)
  [15:0] SOC_WATCHDOG_REFRESH wo — Write a key to reset the watchdog
    0x2B1=SOC_WATCHDOG_REFRESH (Write 16-bit key to reset the watchdog (others values have no effect))
0x78 ACS_SOC_WATCHDOG_COUNT ro — SoC watchdog Counter Current Value
  [23:0] VALUE — SoC watchdog timer current value
0x7C ACS_DBG_STATUS ro — Status of debug enable
  [0] DEBGUG_ENABLE_FLAG — Status flag of debug enable
    0=DEBUG_DISABLE (Debug is enable); 1=DEBUG_ENABLE (Debug is disable)
0x80 ACS_RTC_CLK_STATUS ro — Value of RTC clock
  [0] RTC_CLK_VALUE
0x84 ACS_GP_DATA — JIC RW registers
  [31:0] GP_DATA — 32-bit General-Purpose RW Data
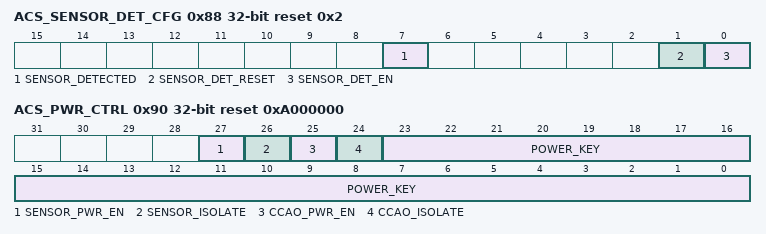
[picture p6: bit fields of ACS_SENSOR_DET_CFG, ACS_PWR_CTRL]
0x88 ACS_SENSOR_DET_CFG reset 0x2 — Sensor detector configuration register
  [7] SENSOR_DETECTED ro — Sensor detected flag
    0=SENSOR_NOT_DETECTED; 1=SENSOR_DETECTED
  [1] SENSOR_DET_RESET — Sensor detector reset
    0=SENSOR_DET_RESET (Wakeup flip-flop is hold in reset state); 1=SENSOR_DET_NOT_RESET (Wakeup flip-flop is active)
  [0] SENSOR_DET_EN — Sensor detector enable
    0=SENSOR_DET_DISABLED (Sensor detector disabled); 1=SENSOR_DET_ENABLED (Sensor detector enabled)
0x8C ACS_NFC_STATUS ro — Status of NFC Field status
  [3:0] HFDET_STATUS — Status of HFDET
0x90 ACS_PWR_CTRL reset 0xA000000 (reset mask 0xF000000) — ACS Power Control Register
  [27] SENSOR_PWR_EN — Sensor power control
    0=ACS_SENSOR_SHUTDOWN (Sensor is powered off); 1=ACS_SENSOR_POWERED (Sensor is powered on)
  [26] SENSOR_ISOLATE — Sensor isolation control
    0=ACS_SENSOR_NOT_ISOLATED (Sensor is not isolated); 1=ACS_SENSOR_ISOLATED (Sensor is isolated)
  [25] CCAO_PWR_EN — CryptoCell always on power control
    0=ACS_CCAO_SHUTDOWN (CryptoCell Always on is powered off); 1=ACS_CCAO_POWERED (CryptoCell Always on is powered on)
  [24] CCAO_ISOLATE — CryptoCell always on isolation control
    0=ACS_CCAO_NOT_ISOLATE (CryptoCell Always on is not isolated); 1=ACS_CCAO_ISOLATE (CryptoCell Always on is isolated)
  [23:0] POWER_KEY wo — Write a key to enable the write to power controls
    0x63412B=ACS_PWR_KEY (Write 24-bit key to enable the write access to power controls)
